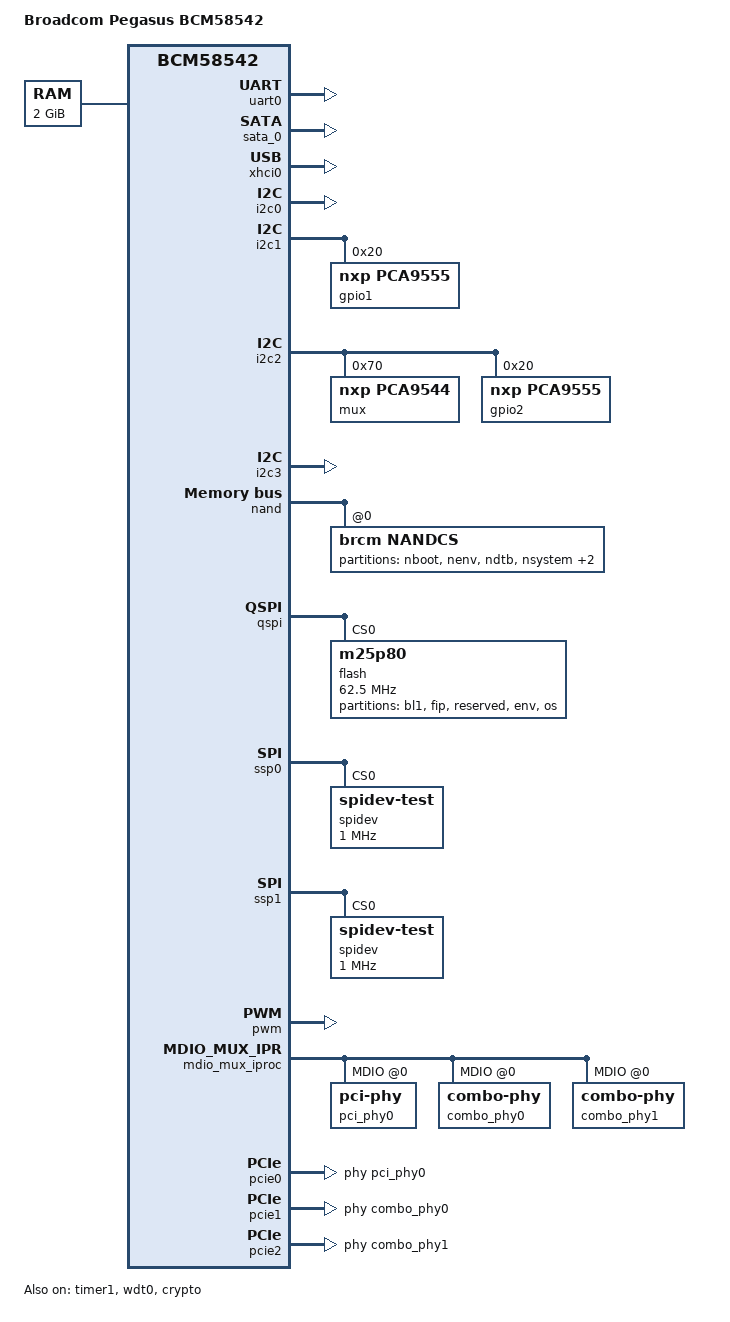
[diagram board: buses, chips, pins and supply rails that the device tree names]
/*
 *  BSD LICENSE
 *
 *  Copyright(c) 2016 Broadcom Limited.  All rights reserved.
 *
 *  Redistribution and use in source and binary forms, with or without
 *  modification, are permitted provided that the following conditions
 *  are met:
 *
 *    * Redistributions of source code must retain the above copyright
 *      notice, this list of conditions and the following disclaimer.
 *    * Redistributions in binary form must reproduce the above copyright
 *      notice, this list of conditions and the following disclaimer in
 *      the documentation and/or other materials provided with the
 *      distribution.
 *    * Neither the name of Broadcom Corporation nor the names of its
 *      contributors may be used to endorse or promote products derived
 *      from this software without specific prior written permission.
 *
 *  THIS SOFTWARE IS PROVIDED BY THE COPYRIGHT HOLDERS AND CONTRIBUTORS
 *  "AS IS" AND ANY EXPRESS OR IMPLIED WARRANTIES, INCLUDING, BUT NOT
 *  LIMITED TO, THE IMPLIED WARRANTIES OF MERCHANTABILITY AND FITNESS FOR
 *  A PARTICULAR PURPOSE ARE DISCLAIMED. IN NO EVENT SHALL THE COPYRIGHT
 *  OWNER OR CONTRIBUTORS BE LIABLE FOR ANY DIRECT, INDIRECT, INCIDENTAL,
 *  SPECIAL, EXEMPLARY, OR CONSEQUENTIAL DAMAGES (INCLUDING, BUT NOT
 *  LIMITED TO, PROCUREMENT OF SUBSTITUTE GOODS OR SERVICES; LOSS OF USE,
 *  DATA, OR PROFITS; OR BUSINESS INTERRUPTION) HOWEVER CAUSED AND ON ANY
 *  THEORY OF LIABILITY, WHETHER IN CONTRACT, STRICT LIABILITY, OR TORT
 *  (INCLUDING NEGLIGENCE OR OTHERWISE) ARISING IN ANY WAY OUT OF THE USE
 * OF THIS SOFTWARE, EVEN IF ADVISED OF THE POSSIBILITY OF SUCH DAMAGE.
 */

/dts-v1/;

/* Reserve the secure memory region */
/memreserve/ 0xA0000000 0x100000;

#include "pegasus.dtsi"

/ {
	model = "Broadcom Pegasus BCM58542";
	compatible = "brcm,bcm58542", "brcm,pegasus";

	chosen {
		bootargs = "maxcpus=4 console=ttyS0,115200n8 debug\
			    earlycon=uart8250,mmio32,0x00300000";
	};

	memory {
		device_type = "memory";
		reg = <0x00000000 0x80000000 0x00000000 0x80000000>;
	};

};

&uart0 {
	status = "ok";
};

&sata_0 {
	status = "ok";
};

&xhci0 {
	status = "ok";
};

&i2c0 {
	status = "ok";
};

&i2c1 {
	status = "ok";
	gpio1: pca9555@20 {
		compatible = "nxp,pca9555";
		reg = <0x20>;
		gpio-controller;
		#gpio-cells = <2>;
	};
};

&i2c2 {
	status = "ok";
	mux@70 {
		compatible = "nxp,pca9544";
		reg = <0x70>;
	};

	gpio2: pca9555@20 {
		compatible = "nxp,pca9555";
		reg = <0x20>;
		gpio-controller;
		#gpio-cells = <2>;
	};
};

&i2c3 {
	status = "ok";
};

&timer1 {
	status = "ok";
};

&wdt0 {
	status = "ok";
};

&dma0 {
	status = "ok";
};


&nand {
	status = "ok";
	nandcs@0 {
		compatible = "brcm,nandcs";
		reg = <0>;
		nand-ecc-mode = "hw";
		nand-ecc-strength = <30>;
		nand-ecc-step-size = <1024>;
		brcm,nand-oob-sector-size = <27>;
		flash-removable;
		#address-cells = <1>;
		#size-cells = <1>;

		partition@0 {
			label = "nboot";
			reg = <0x00000000 0x00280000>; /* 2.5MB */
			read-only;
		};

		partition@280000 {
			label = "nenv";
			reg = <0x00280000 0x00040000>; /* 0.25MB */
			read-only;
		};

		partition@2c0000 {
			label = "ndtb";
			reg = <0x002c0000 0x00040000>; /* 0.25MB */
			read-only;
		};

		partition@300000 {
			label = "nsystem";
			reg = <0x00300000 0x03c00000>; /* 60MB */
			read-only;
		};

		partition@3f00000 {
			label = "reserved";
			reg = <0x03f00000 0x00100000>; /* 1MB */
		};

		partition@4000000 {
			label = "nrootfs";
			reg = <0x04000000 0x3c000000>; /* 960MB */
		};
	};
};

&qspi {
	status = "ok";
	flash: m25p80@0 {
		#address-cells = <1>;
		#size-cells = <1>;
		compatible = "m25p80";
		spi-max-frequency = <62500000>;
		m25p,default-addr-width = <3>;
		reg = <0x0 0x0>;

		partition@0 {
			label = "bl1";
			reg = <0x00000000 0x00020000>; /* 128KB */
		};

		partition@20000 {
			label = "fip";
			reg = <0x00020000 0x000E0000>; /* 896KB */
		};

		partition@100000 {
			label = "reserved";
			reg = <0x00100000 0x000E0000>; /* 896KB */
		};

		partition@1e0000 {
			label = "env";
			reg = <0x001E0000 0x00020000>; /* 128KB */
		};

		partition@200000 {
			label = "os";
			reg = <0x00200000 0x01e00000>; /* 30MB */
		};
	};
};

&gpio_ccg {
	status = "ok";
};

&ssp0 {
	status = "ok";
	spidev@0 {
		compatible = "spidev-test";
		spi-max-frequency = <1000000>;
		reg = <0>;
		spi-cpha = <1>;
		spi-cpol = <1>;
	};
};

&ssp1 {
	status = "ok";
	spidev@0 {
		compatible = "spidev-test";
		spi-max-frequency = <1000000>;
		reg = <0>;
		spi-cpha = <1>;
		spi-cpol = <1>;
	};
};

&pwm {
	status = "ok";
};

&pinctrl {
	status = "ok";
};

&mdio_mux_iproc {
	mdio@0 {
		pci_phy0: pci-phy@0 {
			status = "ok";
		};
	};
	mdio@1 {
		combo_phy0: combo-phy@0 {
			device-type = "pcie";
			status = "ok";
		};
	};
	mdio@2 {
		combo_phy1: combo-phy@0 {
			device-type = "pcie";
			status = "ok";
		};
	};
};

/* Default: PCIe2.0 (2 by 1x + 1 by 2x i.e. x1,x1,x2) */

&pcie0 {
	phys = <&pci_phy0>;
	brcm,pcie-num-lanes = <1>;
	status = "ok";
};

&pcie1 {
	phys = <&combo_phy0>;
	brcm,pcie-num-lanes = <1>;
	/* status = "ok"; */
};

&pcie2 {
	phys = <&combo_phy1>;
	brcm,pcie-num-lanes = <2>;
	/* status = "ok"; */
};

&enet2 {
	status = "disabled";
};

&crypto {
	status = "okay";
};
